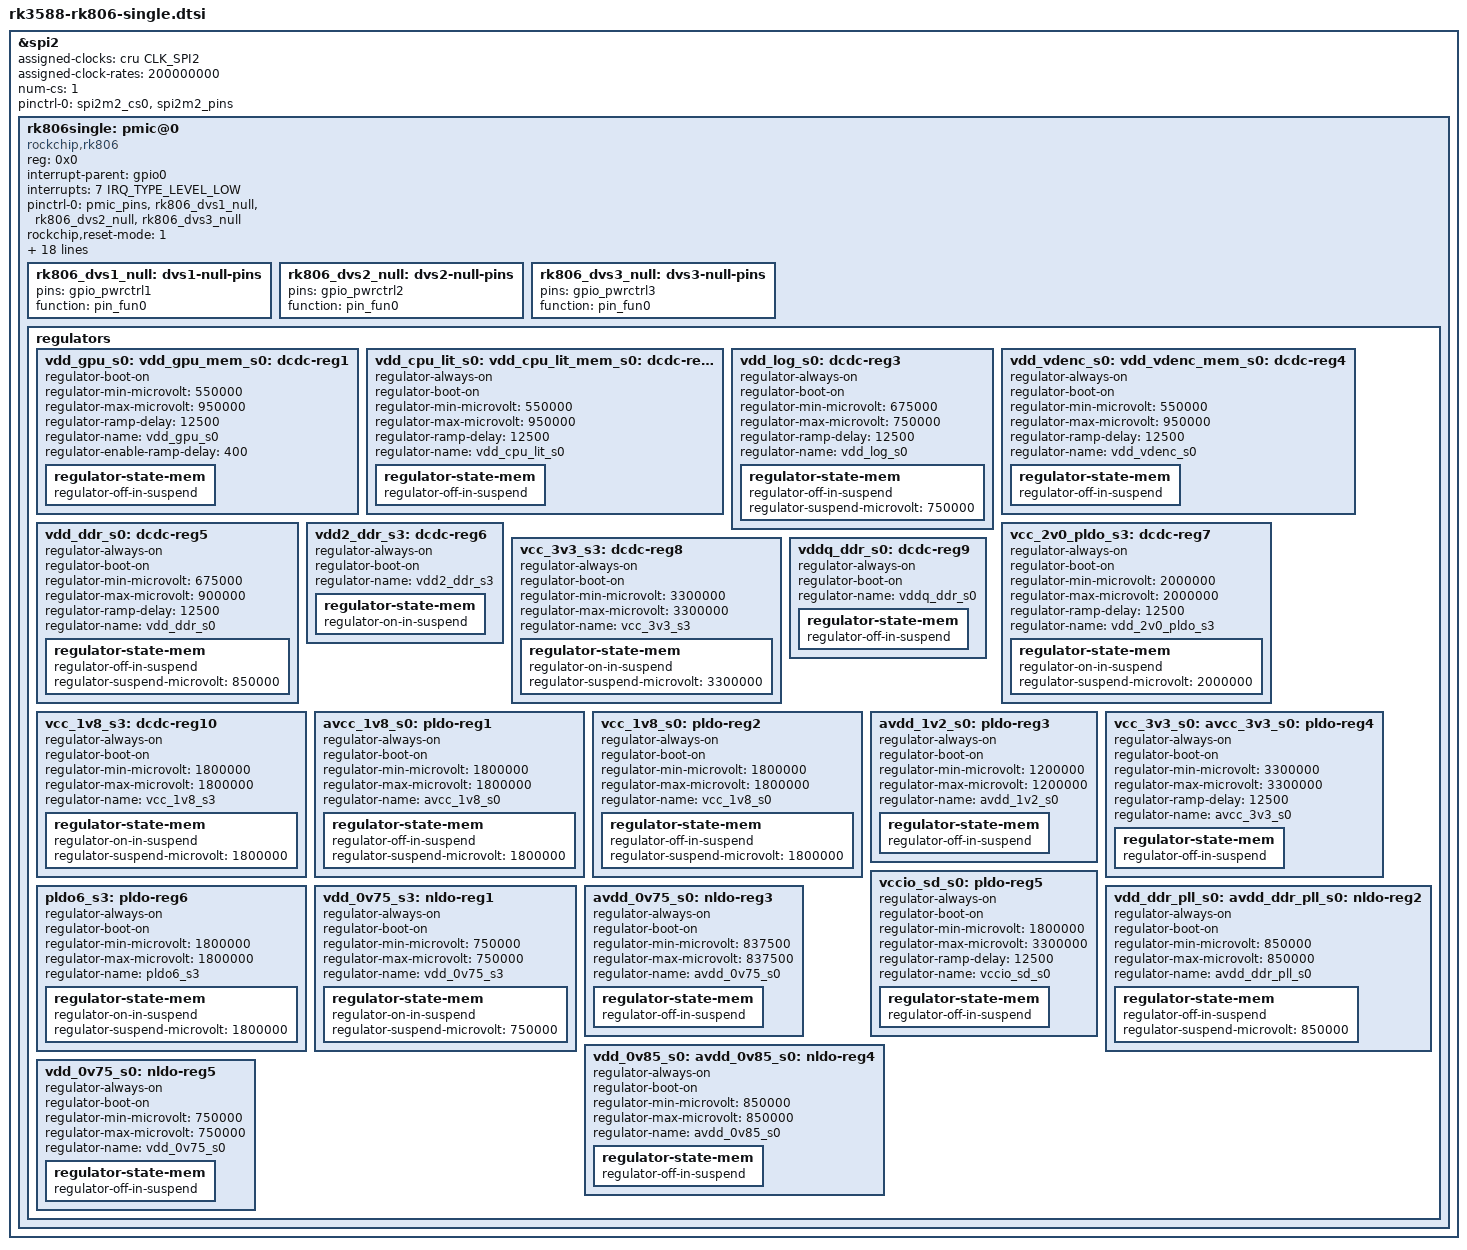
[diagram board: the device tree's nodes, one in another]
// SPDX-License-Identifier: (GPL-2.0+ OR MIT)
/*
 * Copyright (c) 2021 Rockchip Electronics Co., Ltd.
 *
 */

#include <dt-bindings/gpio/gpio.h>
#include <dt-bindings/pinctrl/rockchip.h>

&spi2 {
	assigned-clocks = <&cru CLK_SPI2>;
	assigned-clock-rates = <200000000>;
	num-cs = <1>;
	pinctrl-names = "default";
	pinctrl-0 = <&spi2m2_cs0 &spi2m2_pins>;
	status = "okay";

	rk806single: pmic@0 {
		compatible = "rockchip,rk806";
		reg = <0x0>;

		interrupt-parent = <&gpio0>;
		interrupts = <7 IRQ_TYPE_LEVEL_LOW>;

		pinctrl-names = "default";
		pinctrl-0 = <&pmic_pins>, <&rk806_dvs1_null>,
			    <&rk806_dvs2_null>, <&rk806_dvs3_null>;

		/* 0: restart PMU;
		 * 1: reset all the power off reset registers,
		 *    forcing the state to switch to ACTIVE mode;
		 * 2: Reset all the power off reset registers,
		 *    forcing the state to switch to ACTIVE mode,
		 *    and simultaneously pull down the RESETB PIN for 5mS before releasing
		 */
		// pmic-reset-func = <1>;
		rockchip,reset-mode = <1>; 
		spi-max-frequency = <1000000>;
		system-power-controller;

		vcc1-supply = <&vcc5v0_sys>;
		vcc2-supply = <&vcc5v0_sys>;
		vcc3-supply = <&vcc5v0_sys>;
		vcc4-supply = <&vcc5v0_sys>;
		vcc5-supply = <&vcc5v0_sys>;
		vcc6-supply = <&vcc5v0_sys>;
		vcc7-supply = <&vcc5v0_sys>;
		vcc8-supply = <&vcc5v0_sys>;
		vcc9-supply = <&vcc5v0_sys>;
		vcc10-supply = <&vcc5v0_sys>;
		vcc11-supply = <&vcc_2v0_pldo_s3>;
		vcc12-supply = <&vcc5v0_sys>;
		vcc13-supply = <&vcc_1v1_nldo_s3>;
		vcc14-supply = <&vcc_1v1_nldo_s3>;
		vcca-supply = <&vcc5v0_sys>;

		gpio-controller;
		#gpio-cells = <2>;

		rk806_dvs1_null: dvs1-null-pins {
			pins = "gpio_pwrctrl1";
			function = "pin_fun0";
		};

		rk806_dvs2_null: dvs2-null-pins {
			pins = "gpio_pwrctrl2";
			function = "pin_fun0";
		};

		rk806_dvs3_null: dvs3-null-pins {
			pins = "gpio_pwrctrl3";
			function = "pin_fun0";
		};

		regulators {
			vdd_gpu_s0: vdd_gpu_mem_s0: dcdc-reg1 {
				regulator-boot-on;
				regulator-min-microvolt = <550000>;
				regulator-max-microvolt = <950000>;
				regulator-ramp-delay = <12500>;
				regulator-name = "vdd_gpu_s0";
				regulator-enable-ramp-delay = <400>;

				regulator-state-mem {
					regulator-off-in-suspend;
				};
			};

			vdd_cpu_lit_s0: vdd_cpu_lit_mem_s0: dcdc-reg2 {
				regulator-always-on;
				regulator-boot-on;
				regulator-min-microvolt = <550000>;
				regulator-max-microvolt = <950000>;
				regulator-ramp-delay = <12500>;
				regulator-name = "vdd_cpu_lit_s0";

				regulator-state-mem {
					regulator-off-in-suspend;
				};
			};

			vdd_log_s0: dcdc-reg3 {
				regulator-always-on;
				regulator-boot-on;
				regulator-min-microvolt = <675000>;
				regulator-max-microvolt = <750000>;
				regulator-ramp-delay = <12500>;
				regulator-name = "vdd_log_s0";

				regulator-state-mem {
					regulator-off-in-suspend;
					regulator-suspend-microvolt = <750000>;
				};
			};

			vdd_vdenc_s0: vdd_vdenc_mem_s0: dcdc-reg4 {
				regulator-always-on;
				regulator-boot-on;
				regulator-min-microvolt = <550000>;
				regulator-max-microvolt = <950000>;
				regulator-ramp-delay = <12500>;
				regulator-name = "vdd_vdenc_s0";

				regulator-state-mem {
					regulator-off-in-suspend;
				};
			};

			vdd_ddr_s0: dcdc-reg5 {
				regulator-always-on;
				regulator-boot-on;
				regulator-min-microvolt = <675000>;
				regulator-max-microvolt = <900000>;
				regulator-ramp-delay = <12500>;
				regulator-name = "vdd_ddr_s0";

				regulator-state-mem {
					regulator-off-in-suspend;
					regulator-suspend-microvolt = <850000>;
				};
			};

			vdd2_ddr_s3: dcdc-reg6 {
				regulator-always-on;
				regulator-boot-on;
				regulator-name = "vdd2_ddr_s3";

				regulator-state-mem {
					regulator-on-in-suspend;
				};
			};

			vcc_2v0_pldo_s3: dcdc-reg7 {
				regulator-always-on;
				regulator-boot-on;
				regulator-min-microvolt = <2000000>;
				regulator-max-microvolt = <2000000>;
				regulator-ramp-delay = <12500>;
				regulator-name = "vdd_2v0_pldo_s3";

				regulator-state-mem {
					regulator-on-in-suspend;
					regulator-suspend-microvolt = <2000000>;
				};
			};

			vcc_3v3_s3: dcdc-reg8 {
				regulator-always-on;
				regulator-boot-on;
				regulator-min-microvolt = <3300000>;
				regulator-max-microvolt = <3300000>;
				regulator-name = "vcc_3v3_s3";

				regulator-state-mem {
					regulator-on-in-suspend;
					regulator-suspend-microvolt = <3300000>;
				};
			};

			vddq_ddr_s0: dcdc-reg9 {
				regulator-always-on;
				regulator-boot-on;
				regulator-name = "vddq_ddr_s0";

				regulator-state-mem {
					regulator-off-in-suspend;
				};
			};

			vcc_1v8_s3: dcdc-reg10 {
				regulator-always-on;
				regulator-boot-on;
				regulator-min-microvolt = <1800000>;
				regulator-max-microvolt = <1800000>;
				regulator-name = "vcc_1v8_s3";

				regulator-state-mem {
					regulator-on-in-suspend;
					regulator-suspend-microvolt = <1800000>;
				};
			};

			avcc_1v8_s0: pldo-reg1 {
				regulator-always-on;
				regulator-boot-on;
				regulator-min-microvolt = <1800000>;
				regulator-max-microvolt = <1800000>;
				regulator-name = "avcc_1v8_s0";

				regulator-state-mem {
					regulator-off-in-suspend;
					regulator-suspend-microvolt = <1800000>;
				};
			};

			vcc_1v8_s0: pldo-reg2 {
				regulator-always-on;
				regulator-boot-on;
				regulator-min-microvolt = <1800000>;
				regulator-max-microvolt = <1800000>;
				regulator-name = "vcc_1v8_s0";

				regulator-state-mem {
					regulator-off-in-suspend;
					regulator-suspend-microvolt = <1800000>;
				};
			};

			avdd_1v2_s0: pldo-reg3 {
				regulator-always-on;
				regulator-boot-on;
				regulator-min-microvolt = <1200000>;
				regulator-max-microvolt = <1200000>;
				regulator-name = "avdd_1v2_s0";

				regulator-state-mem {
					regulator-off-in-suspend;
				};
			};

			vcc_3v3_s0: avcc_3v3_s0: pldo-reg4 {
				regulator-always-on;
				regulator-boot-on;
				regulator-min-microvolt = <3300000>;
				regulator-max-microvolt = <3300000>;
				regulator-ramp-delay = <12500>;
				regulator-name = "avcc_3v3_s0";

				regulator-state-mem {
					regulator-off-in-suspend;
				};
			};

			vccio_sd_s0: pldo-reg5 {
				regulator-always-on;
				regulator-boot-on;
				regulator-min-microvolt = <1800000>;
				regulator-max-microvolt = <3300000>;
				regulator-ramp-delay = <12500>;
				regulator-name = "vccio_sd_s0";

				regulator-state-mem {
					regulator-off-in-suspend;
				};
			};

			pldo6_s3: pldo-reg6 {
				regulator-always-on;
				regulator-boot-on;
				regulator-min-microvolt = <1800000>;
				regulator-max-microvolt = <1800000>;
				regulator-name = "pldo6_s3";

				regulator-state-mem {
					regulator-on-in-suspend;
					regulator-suspend-microvolt = <1800000>;
				};
			};

			vdd_0v75_s3: nldo-reg1 {
				regulator-always-on;
				regulator-boot-on;
				regulator-min-microvolt = <750000>;
				regulator-max-microvolt = <750000>;
				regulator-name = "vdd_0v75_s3";

				regulator-state-mem {
					regulator-on-in-suspend;
					regulator-suspend-microvolt = <750000>;
				};
			};

			vdd_ddr_pll_s0: avdd_ddr_pll_s0: nldo-reg2 {
				regulator-always-on;
				regulator-boot-on;
				regulator-min-microvolt = <850000>;
				regulator-max-microvolt = <850000>;
				regulator-name = "avdd_ddr_pll_s0";

				regulator-state-mem {
					regulator-off-in-suspend;
					regulator-suspend-microvolt = <850000>;
				};
			};

			avdd_0v75_s0: nldo-reg3 {
				regulator-always-on;
				regulator-boot-on;
				regulator-min-microvolt = <837500>;
				regulator-max-microvolt = <837500>;
				regulator-name = "avdd_0v75_s0";

				regulator-state-mem {
					regulator-off-in-suspend;
				};
			};

			vdd_0v85_s0: avdd_0v85_s0: nldo-reg4 {
				regulator-always-on;
				regulator-boot-on;
				regulator-min-microvolt = <850000>;
				regulator-max-microvolt = <850000>;
				regulator-name = "avdd_0v85_s0";

				regulator-state-mem {
					regulator-off-in-suspend;
				};
			};

			vdd_0v75_s0: nldo-reg5 {
				regulator-always-on;
				regulator-boot-on;
				regulator-min-microvolt = <750000>;
				regulator-max-microvolt = <750000>;
				regulator-name = "vdd_0v75_s0";

				regulator-state-mem {
					regulator-off-in-suspend;
				};
			};
		};
	};
};
